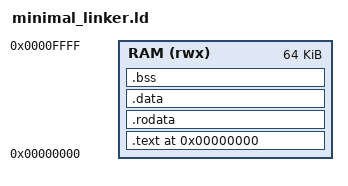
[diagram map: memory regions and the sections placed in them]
OUTPUT_ARCH(riscv)
ENTRY(_start)

MEMORY
{
  RAM (rwx) : ORIGIN = 0x00000000, LENGTH = 64K
}

SECTIONS
{
  . = ORIGIN(RAM);
  .text : {
    KEEP(*(.text.start))
    *(.text .text.*)
  } > RAM

  .rodata : { *(.rodata .rodata.*) } > RAM
  .data   : { *(.data .data.*) } > RAM
  .bss (NOLOAD) : {
    *(.bss .bss.* COMMON)
  } > RAM
}
